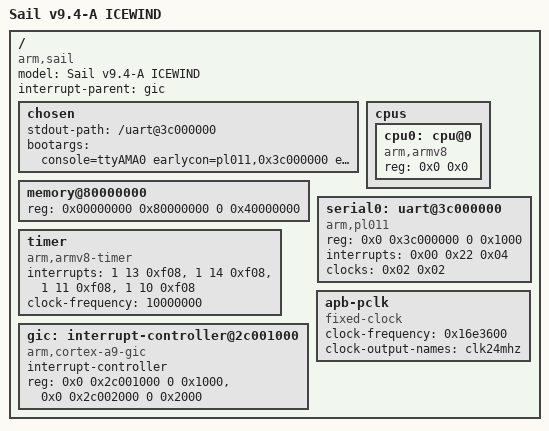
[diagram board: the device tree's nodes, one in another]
// SPDX-License-Identifier: GPL-2.0
/*
 * ARM Ltd.
 *
 * ARMv8 Foundation model DTS
 */

/dts-v1/;

/ {
	model = "Sail v9.4-A ICEWIND";
	compatible = "arm,sail";
	interrupt-parent = <&gic>;
	#address-cells = <2>;
	#size-cells = <2>;

	chosen {
		stdout-path = "/uart@3c000000";
	    bootargs = "console=ttyAMA0 earlycon=pl011,0x3c000000 earlyprintk=pl011,0x3c000000 loglevel=9 debug acpi=off sched_debug nohlt root=/dev/vda nokaslr norandmaps page_alloc.shuffle=false randomize_kstack_offset=false";
	};

	cpus {
		#address-cells = <2>;
		#size-cells = <0>;

		cpu0: cpu@0 {
			device_type = "cpu";
			compatible = "arm,armv8";
			reg = <0x0 0x0>;
		};
	};

	memory@80000000 {
		device_type = "memory";
		reg = <0x00000000 0x80000000 0 0x40000000>;
	};

	serial0: uart@3c000000 {
		compatible = "arm,pl011", "arm,primecell";
		reg = <0x0 0x3c000000 0 0x1000>;
		interrupts = <0x00 0x22 0x04>;
		clocks = <0x02 0x02>;
		clock-names = "uartclk\0apb_pclk";
	};

	timer {
		compatible = "arm,armv8-timer";
		interrupts = <1 13 0xf08>,
			     <1 14 0xf08>,
			     <1 11 0xf08>,
			     <1 10 0xf08>;
		clock-frequency = <10000000>;
	};

	gic: interrupt-controller@2c001000 {
		compatible = "arm,cortex-a9-gic";
		#interrupt-cells = <3>;
		#address-cells = <2>;
		interrupt-controller;
		reg = <0x0 0x2c001000 0 0x1000>,
		      <0x0 0x2c002000 0 0x2000>;
	};

/*	virtio_block@3d000000 {
*		compatible = "virtio,mmio";
*		reg = <0x00 0x3d000000 0x00 0x1000>;
*		interrupts = <0x00 0x20 0x04>;
*	};
*/

	apb-pclk {
		compatible = "fixed-clock";
		#clock-cells = <0x00>;
		clock-frequency = <0x16e3600>;
		clock-output-names = "clk24mhz";
		phandle = <0x02>;
	};
};
